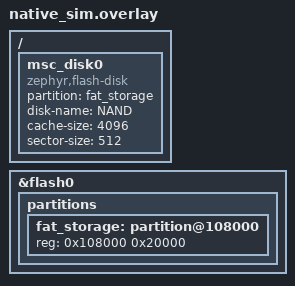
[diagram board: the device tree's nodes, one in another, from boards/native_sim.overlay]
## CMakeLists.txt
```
# SPDX-License-Identifier: Apache-2.0

cmake_minimum_required(VERSION 3.20.0)
find_package(Zephyr REQUIRED HINTS $ENV{ZEPHYR_BASE})
project(fat_corrupt_tests)

# The patched flashdisk driver copy (fw/drivers/flashdisk, issue #380).
add_subdirectory(
	${CMAKE_CURRENT_LIST_DIR}/../../../drivers
	${CMAKE_CURRENT_BINARY_DIR}/app_drivers
)

target_sources(app PRIVATE src/main.cpp)
target_sources(app PRIVATE ${CMAKE_CURRENT_LIST_DIR}/../../../src/storage/storage.cpp)

target_include_directories(app PRIVATE ${CMAKE_CURRENT_LIST_DIR}/../../../src)
```

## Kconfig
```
source "Kconfig.zephyr"

# For CONFIG_DISK_DRIVER_FLASH_PATCHED (the issue #380 flashdisk backport).
rsource "../../../drivers/Kconfig"

# storage.cpp gates storage_fat_corrupt_boot_sector() on this symbol, which is defined in
# fw/Kconfig — invisible to a standalone Twister app, so it is redeclared here.
#
# Unlike the int mirrors elsewhere in fw/tests, this one cannot drift into a wrong VALUE:
# the suite exists to test the gated function, so `y` is the only setting that builds
# anything. If the gate symbol is ever renamed, this fails loudly at configure time
# ("attempt to assign the value 'y' to the undefined symbol ..."), which is how it was
# found in the first place.
config APP_CRASH_TEST_COMMANDS
	bool "Shell commands that deliberately crash the firmware"
	default y
```

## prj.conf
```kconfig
CONFIG_ZTEST=y
CONFIG_CPP=y
CONFIG_STD_CPP2B=y
CONFIG_REQUIRES_FULL_LIBCPP=y
CONFIG_REQUIRES_FULL_LIBC=y
CONFIG_FLASH=y
CONFIG_FLASH_MAP=y
CONFIG_FILE_SYSTEM=y
CONFIG_FAT_FILESYSTEM_ELM=y
CONFIG_FILE_SYSTEM_MKFS=y
CONFIG_DISK_ACCESS=y
# Patched flashdisk copy (issue #380) instead of the SDK driver, same as the
# proto0 board conf — so this suite exercises the driver the device runs.
CONFIG_DISK_DRIVER_FLASH=n
CONFIG_DISK_DRIVER_FLASH_PATCHED=y
CONFIG_HEAP_MEM_POOL_SIZE=16384

# storage_fat_corrupt_boot_sector() is gated on this symbol, same as the shell command.
CONFIG_APP_CRASH_TEST_COMMANDS=y
```

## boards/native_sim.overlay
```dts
/*
 * A fat_storage partition plus the zephyr,flash-disk node that binds it to the "NAND"
 * disk, so FIXED_PARTITION_ID(fat_storage) and disk_access_ioctl("NAND", ...) resolve
 * the same way they do on proto0 (where the partition comes from pm_static YAML and the
 * disk node lives in the board DTS).
 */
/ {
	msc_disk0 {
		compatible = "zephyr,flash-disk";
		partition = <&fat_storage>;
		disk-name = "NAND";
		cache-size = <4096>;
		sector-size = <512>;
	};
};

&flash0 {
	partitions {
		fat_storage: partition@108000 {
			reg = <0x108000 0x20000>;
		};
	};
};
```

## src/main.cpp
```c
/*
 * Coverage for storage_fat_corrupt_boot_sector() — the flash half of the
 * `fatfs corrupt` test aid.
 *
 * The command's whole value is that it CANNOT silently no-op: a test aid that reports
 * success while the volume stays mountable makes the next boot look like it exercised the
 * auto-format path when it never did. So these tests assert the two properties that carry
 * that guarantee — the signature is really gone, and a surviving signature is reported as
 * a failure rather than swallowed — plus idempotency, since the command deliberately
 * leaves the volume unmounted and re-arming it is a normal thing to do.
 */

#include <storage/storage.h>

#include <zephyr/fs/fs.h>
#include <zephyr/storage/flash_map.h>
#include <zephyr/ztest.h>

#include <cstring>

namespace {

constexpr off_t kBootSignatureOff = 510;

/* Writes a plausible FAT boot signature so the erase has something real to remove.
 * flash_area_write needs an erased target, so erase the sector first. */
void seed_boot_signature(void) {
    const struct flash_area *fa = nullptr;
    zassert_ok(flash_area_open(FIXED_PARTITION_ID(fat_storage), &fa), "open failed");
    zassert_ok(flash_area_erase(fa, 0, 4096), "pre-erase failed");

    /* 0xAA55 little-endian at 510 is what FatFs checks to decide the volume is
     * mountable — it is the exact byte pair the helper has to destroy. */
    const uint8_t sig[2] = {0x55, 0xAA};
    zassert_ok(flash_area_write(fa, kBootSignatureOff, sig, sizeof(sig)), "write failed");
    flash_area_close(fa);
}

bool signature_present(void) {
    const struct flash_area *fa = nullptr;
    zassert_ok(flash_area_open(FIXED_PARTITION_ID(fat_storage), &fa), "open failed");
    uint8_t sig[2] = {0, 0};
    zassert_ok(flash_area_read(fa, kBootSignatureOff, sig, sizeof(sig)), "read failed");
    flash_area_close(fa);
    return sig[0] == 0x55 && sig[1] == 0xAA;
}

}  // namespace

ZTEST_SUITE(fat_corrupt_tests, NULL, NULL, NULL, NULL, NULL);

/* The property the command asserts to its operator: after a success return, the volume is
 * genuinely unmountable. */
ZTEST(fat_corrupt_tests, test_erases_the_boot_signature) {
    seed_boot_signature();
    zassert_true(signature_present(), "setup: the signature should be there to begin with");

    zassert_ok(storage_fat_corrupt_boot_sector(), "corrupt should succeed");

    zassert_false(signature_present(), "the 0xAA55 signature must be gone");
}

/* The first flash sector must be fully erased, not just the two signature bytes — the FAT
 * itself lives in this sector too (FM_SFD, 512-byte disk sectors, so page 0 holds the boot
 * sector plus FAT sectors 1-7). */
ZTEST(fat_corrupt_tests, test_erases_the_whole_first_sector) {
    seed_boot_signature();
    zassert_ok(storage_fat_corrupt_boot_sector());

    const struct flash_area *fa = nullptr;
    zassert_ok(flash_area_open(FIXED_PARTITION_ID(fat_storage), &fa));
    uint8_t buf[256];
    for (off_t off = 0; off < 4096; off += static_cast<off_t>(sizeof(buf))) {
        zassert_ok(flash_area_read(fa, off, buf, sizeof(buf)), "read at %ld failed", (long)off);
        for (size_t i = 0; i < sizeof(buf); i++) {
            zassert_equal(buf[i], 0xFF, "byte at %ld not erased: 0x%02x", (long)(off + i),
                          buf[i]);
        }
    }
    flash_area_close(fa);
}

/* Re-arming must work. The command leaves the volume unmounted by design, so running it
 * twice without a reboot is a normal operator action — and the unmount guard in the shell
 * wrapper exists precisely because the naive version aborted on the second run. Erasing an
 * already-erased sector must stay a clean success, not an error. */
ZTEST(fat_corrupt_tests, test_is_idempotent) {
    seed_boot_signature();
    zassert_ok(storage_fat_corrupt_boot_sector(), "first call should succeed");
    zassert_ok(storage_fat_corrupt_boot_sector(), "second call should also succeed");
    zassert_false(signature_present());
}

/* On a volume that never had a signature, success is still the honest answer: the
 * post-condition the caller cares about ("this will not mount") already holds. */
ZTEST(fat_corrupt_tests, test_succeeds_on_an_already_blank_volume) {
    const struct flash_area *fa = nullptr;
    zassert_ok(flash_area_open(FIXED_PARTITION_ID(fat_storage), &fa));
    zassert_ok(flash_area_erase(fa, 0, 4096));
    flash_area_close(fa);

    zassert_ok(storage_fat_corrupt_boot_sector());
    zassert_false(signature_present());
}
```
